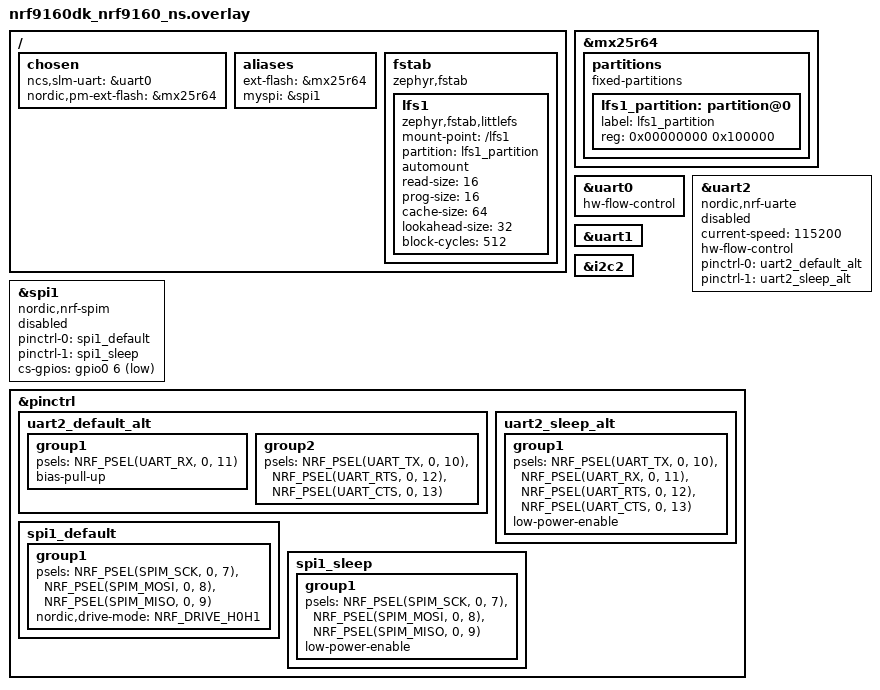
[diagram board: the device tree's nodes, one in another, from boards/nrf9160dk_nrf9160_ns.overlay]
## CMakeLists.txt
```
#
# Copyright (c) 2019 Nordic Semiconductor
#
# SPDX-License-Identifier: LicenseRef-Nordic-5-Clause
#

cmake_minimum_required(VERSION 3.20.0)

find_package(Zephyr REQUIRED HINTS $ENV{ZEPHYR_BASE})
project(serial_lte_modem)

# NORDIC SDK APP START
target_sources(app PRIVATE src/main.c)
target_sources(app PRIVATE src/slm_util.c)
target_sources(app PRIVATE src/slm_settings.c)
target_sources(app PRIVATE src/slm_at_host.c)
target_sources(app PRIVATE src/slm_at_commands.c)
# target_sources(app PRIVATE src/slm_at_socket.c)
# target_sources(app PRIVATE src/slm_at_tcp_proxy.c)
# target_sources(app PRIVATE src/slm_at_udp_proxy.c)
# target_sources(app PRIVATE src/slm_at_icmp.c)
target_sources(app PRIVATE src/slm_at_fota.c)
target_sources(app PRIVATE src/slm_uart_handler.c)
target_sources(app PRIVATE src/nvs_thread.c)
target_sources(app PRIVATE src/littlefs_thread.c)
# NORDIC SDK APP END
target_sources_ifdef(CONFIG_EXAMPLE_SPI app
                     PRIVATE src/spi_thread.c)					 
target_sources_ifdef(CONFIG_EXAMPLE_UART app
                     PRIVATE src/uart_thread.c)
target_sources_ifdef(CONFIG_SLM_SMS app PRIVATE src/slm_at_sms.c)
target_sources_ifdef(CONFIG_SLM_PPP app PRIVATE src/slm_ppp.c)
target_sources_ifdef(CONFIG_SLM_CMUX app PRIVATE src/slm_cmux.c)

add_subdirectory_ifdef(CONFIG_SLM_GNSS src/gnss)
add_subdirectory_ifdef(CONFIG_SLM_NRF_CLOUD src/nrfcloud)
add_subdirectory_ifdef(CONFIG_SLM_MQTTC src/mqtt_c)
add_subdirectory_ifdef(CONFIG_SLM_HTTPC src/http_c)
add_subdirectory_ifdef(CONFIG_SLM_TWI src/twi)
add_subdirectory_ifdef(CONFIG_SLM_GPIO src/gpio)
add_subdirectory_ifdef(CONFIG_SLM_CARRIER src/lwm2m_carrier)
add_subdirectory_ifdef(CONFIG_SLM_NATIVE_TLS src/nativetls)
if (CONFIG_SLM_FTPC OR CONFIG_SLM_TFTPC)
        add_subdirectory(src/ftp_c)
endif()

zephyr_include_directories(src)
```

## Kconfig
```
#
# Copyright (c) 2019 Nordic Semiconductor
#
# SPDX-License-Identifier: LicenseRef-Nordic-5-Clause
#

source "Kconfig.zephyr"

menu "Nordic Serial LTE Modem"

config EXAMPLE_SPI
	bool "load SPI master example or not"
	help
		if yes, load SPI master example

config EXAMPLE_UART
	bool "load high speed UART example or not"
	help
		if yes, load high speed UART example

config APP_WIPE_STORAGE
	bool "Option to clear the flash area before mounting"
	help
	  Use this to force an existing file system to be created.

choice
	prompt "Storage backend type used by the application"
	default APP_LITTLEFS_STORAGE_FLASH
	help
	  Specify the type of storage backend.

config APP_LITTLEFS_STORAGE_FLASH
	bool "Use flash memory backend"

config APP_LITTLEFS_STORAGE_BLK_SDMMC
	bool "Use block device (e.g. SD MMC) backend"
endchoice	

config SLM_CUSTOMER_VERSION
	string "Customer version string"
	help
	   This version is reported together with baseline versions by AT command "#XSLMVER".

config SLM_AT_MAX_PARAM
	int "Maximum number of parameters in AT command"
	default 42

#
# external XTAL for UART
#
config SLM_EXTERNAL_XTAL
	bool "Use external XTAL for UARTE"
	default y

#
# AT command terminator
#
choice
	prompt "Termination mode"
	default SLM_CR_LF_TERMINATION
	help
		Sets the command terminator used by the serial terminal.
		Available options are:
		-  CR termination
		-  LF termination
		-  CR+LF termination
	config SLM_CR_TERMINATION
		bool "CR termination"
	config SLM_LF_TERMINATION
		bool "LF termination"
	config SLM_CR_LF_TERMINATION
		bool "CR+LF termination"
endchoice

#
# UART buffers (when CMUX is not in use)
#
config SLM_UART_RX_BUF_COUNT
	int "Receive buffers for UART"
	range 2 4
	default 3
	help
	  Amount of buffers for receiving (RX) UART traffic. If the buffers are full, UART RX will be disabled until the buffers are processed.

config SLM_UART_RX_BUF_SIZE
	int "Receive buffer size for UART"
	range 128 4096
	default 256
	help
	  Amount of received (RX), unprocessed, UART traffic that can be held by single buffer.

config SLM_UART_TX_BUF_SIZE
	int "Send buffer size for UART"
	range 128 4096
	default 256
	help
	  Amount of UART traffic waiting to be sent (TX), that can be held. If the buffers are full, will send synchronously.

#
# GPIO functionality
#
config SLM_START_SLEEP
	bool "Enter sleep on startup"
	help
	  If enabled, the SiP is put into deep sleep when powered on.
	  It can then be started using SLM_POWER_PIN.

config SLM_POWER_PIN
	int "Power pin"
	default -1
	help
	  Interface GPIO pin used to put the SiP into deep sleep and wake up from it or exit idle.
	  The pin is configured with a pull up and must be pulled down shortly to perform one power off or wake up operation.

config SLM_INDICATE_PIN
	int "Indicate pin"
	default -1
	help
	  Interface GPIO pin used to indicate that data is available when SLM is idle (after #XSLEEP=2 AT command).

config SLM_INDICATE_TIME
	int "Indication period"
	default 100
	help
	  GPIO active indication time in milliseconds. This setting specify the period length for the pin to be active

#
# LTE network automatic attach
#
config SLM_AUTO_CONNECT
	bool "Automatically connect to the LTE network on start-up or after a reset"
	help
	  Enables automatic connection to the LTE network using the PDN configuration defined in 'slm_auto_connect.h'.

#
# TCP/TLS proxy
#
config SLM_TCP_POLL_TIME
	int "Poll time-out in seconds for TCP connection"
	default 10

config SLM_UDP_POLL_TIME
	int "Poll time-out in seconds for UDP connection"
	default 10

#
# Data mode
#
config SLM_DATAMODE_TERMINATOR
	string "Pattern string to terminate data mode"
	default "+++"
	help
	  Use a pattern to terminate data mode

config SLM_DATAMODE_URC
	bool "Send URC in data mode"
	help
	  Report result of data mode sending

config SLM_DATAMODE_BUF_SIZE
	int "Buffer size for data mode"
	range 1024 8192
	default 4096
	help
	  Size of the buffer for data received in data mode.

#
# Configurable services
#
config SLM_SMS
	bool "SMS support in SLM"
	default y
	select SMS
	help
	  Support SMS send/receive in plain text

config SLM_GNSS
	bool "GNSS support in SLM"
	default y

config SLM_NRF_CLOUD
	bool "nRF Cloud support in SLM"
	default y

config SLM_FULL_FOTA
	bool "Full modem FOTA support in SLM"
	default n
	depends on !BOARD_THINGY91_NRF9160_NS

config SLM_PPP
	bool "PPP support in SLM"
	help
	  When enabled, SLM automatically brings up/down the PPP link
	  when the LTE link (default PDN) is connected/disconnected,
	  regardless of what is done with AT#XPPP.

if SLM_PPP

config SLM_PPP_FALLBACK_MTU
	int "Fallback MTU to be used by PPP"
	default 1280
	help
	  PPP tries to retrieve the cellular link MTU from the modem (using `AT+CGCONTRDP=0`).
	  If no MTU is returned by the modem, this value will be used as a fallback.
	  The MTU will be used for sending and receiving of data on both the PPP and cellular links.

endif

config SLM_CMUX
	bool "CMUX support in SLM"

if SLM_CMUX && SLM_PPP

config SLM_CMUX_AUTOMATIC_FALLBACK_ON_PPP_STOPPAGE
	bool "AT channel automatic fallback to DLCI 1 when PPP stops."
	help
	  This is mainly intended for compatibility with Zephyr's cellular modem driver.
	  If enabled, when PPP stops (which happens automatically when the LTE link goes down)
	  CMUX will make the AT channel be on DLCI 1. This only has an effect if it had been
	  configured to be elsewhere, e.g. with AT#XCMUX=2.

endif

if SLM_CMUX || SLM_PPP

config SLM_MODEM_PIPE_TIMEOUT
	int "Timeout for the CMUX and PPP modem pipe operations in seconds"
	default 10

endif

module = SLM
module-str = serial modem
source "${ZEPHYR_BASE}/subsys/logging/Kconfig.template.log_config"

rsource "src/ftp_c/Kconfig"
rsource "src/mqtt_c/Kconfig"
rsource "src/http_c/Kconfig"
rsource "src/twi/Kconfig"
rsource "src/gpio/Kconfig"
rsource "src/lwm2m_carrier/Kconfig"
rsource "src/gnss/Kconfig"
rsource "src/nativetls/Kconfig"

endmenu
```

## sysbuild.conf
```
#
# Copyright (c) 2023 Nordic Semiconductor
#
# SPDX-License-Identifier: LicenseRef-Nordic-5-Clause
#

SB_CONFIG_BOOTLOADER_MCUBOOT=y
SB_CONFIG_PM_EXTERNAL_FLASH_MCUBOOT_SECONDARY=y
```

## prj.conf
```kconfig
#
# Copyright (c) 2020 Nordic Semiconductor ASA
#
# SPDX-License-Identifier: LicenseRef-Nordic-5-Clause
#
# General config
CONFIG_LOG=y
CONFIG_LOG_DEFAULT_LEVEL=3
CONFIG_STACK_SENTINEL=y
CONFIG_PICOLIBC_IO_FLOAT=y
CONFIG_RING_BUFFER=y
CONFIG_REBOOT=y
CONFIG_EVENTFD=y

# Segger RTT
CONFIG_USE_SEGGER_RTT=y
# Where console messages (printk) are output.
# By itself, SLM does not output any.
CONFIG_RTT_CONSOLE=y
CONFIG_UART_CONSOLE=y
# Where SLM logs are output.
CONFIG_LOG_BACKEND_RTT=y
CONFIG_LOG_BACKEND_UART=y

# Network
CONFIG_NETWORKING=y
CONFIG_NET_SOCKETS=y
CONFIG_NET_NATIVE=n
CONFIG_NET_IPV4=y
CONFIG_NET_IPV6=y

# Modem library
CONFIG_NRF_MODEM_LIB=y
CONFIG_AT_CMD_CUSTOM=y
# Align the max FD entry to NRF_MODEM_MAX_SOCKET_COUNT(8)
CONFIG_ZVFS_OPEN_MAX=8

# Handle modem fault
CONFIG_NRF_MODEM_LIB_ON_FAULT_APPLICATION_SPECIFIC=y

# Use GPIO
CONFIG_GPIO=y
CONFIG_GPIO_NRFX=y

# UART interface
CONFIG_SERIAL=y
CONFIG_UART_USE_RUNTIME_CONFIGURE=y
CONFIG_UART_ASYNC_API=y
CONFIG_NRFX_TIMER2=y

# Stacks and heaps
CONFIG_MAIN_STACK_SIZE=4096
CONFIG_HEAP_MEM_POOL_SIZE=16384
CONFIG_SYSTEM_WORKQUEUE_STACK_SIZE=4096
#CONFIG_AT_MONITOR_HEAP_SIZE=4096
CONFIG_AT_MONITOR_HEAP_SIZE=1024

# Device power management
CONFIG_PM_DEVICE=y

# FOTA
CONFIG_HTTP_PARSER_URL=y
CONFIG_FOTA_DOWNLOAD=y
CONFIG_FOTA_DOWNLOAD_PROGRESS_EVT=y
CONFIG_DFU_TARGET=y
CONFIG_DOWNLOAD_CLIENT=y
CONFIG_DOWNLOAD_CLIENT_STACK_SIZE=4096
CONFIG_DOWNLOAD_CLIENT_MAX_FILENAME_SIZE=2048
CONFIG_BOOTLOADER_MCUBOOT=y
CONFIG_IMG_MANAGER=y

# FLASH
CONFIG_FLASH=y
CONFIG_FLASH_PAGE_LAYOUT=y
CONFIG_FLASH_MAP=y
CONFIG_STREAM_FLASH=y
CONFIG_MPU_ALLOW_FLASH_WRITE=y
CONFIG_IMG_ERASE_PROGRESSIVELY=y

# Settings
CONFIG_SETTINGS=y
CONFIG_SETTINGS_NVS=y
CONFIG_NVS=y

# nRF Cloud
CONFIG_NRF_CLOUD_MQTT=n
CONFIG_NRF_CLOUD_FOTA=n
CONFIG_NRF_CLOUD_AGNSS=n
CONFIG_NRF_CLOUD_AGNSS_FILTERED=n
CONFIG_NRF_CLOUD_PGPS=n
CONFIG_NRF_CLOUD_LOCATION=n
CONFIG_NRF_CLOUD_LOG_LEVEL_INF=y
CONFIG_NRF_CLOUD_GPS_LOG_LEVEL_INF=y
CONFIG_NRF_CLOUD_CLIENT_ID_SRC_INTERNAL_UUID=y
CONFIG_NRF_CLOUD_WIFI_LOCATION_ENCODE_OPT_MAC_RSSI=y
CONFIG_DATE_TIME=n
CONFIG_MODEM_INFO=n
CONFIG_MODEM_INFO_ADD_DATE_TIME=n

# UUID and JWT
CONFIG_MODEM_JWT=y

# MQTT client
#CONFIG_MQTT_KEEPALIVE=60
CONFIG_MQTT_CLEAN_SESSION=y

# AT command helper libraries
CONFIG_AT_PARSER=y
CONFIG_AT_MONITOR=y

# Disable TF-M logging.
# TF-M log sending will block until remote end is ready, when HWFC is used on UART1.
CONFIG_TFM_LOG_LEVEL_SILENCE=y

#
# SLM-specific configurations
#
CONFIG_SLM_CUSTOMER_VERSION=""
CONFIG_SLM_EXTERNAL_XTAL=n

# debug options
#CONFIG_ASSERT=y
#CONFIG_LOG_BUFFER_SIZE=16384
#CONFIG_SLM_LOG_LEVEL_DBG=y
#CONFIG_LOG_PRINTK=n
#CONFIG_LOG_MODE_IMMEDIATE=y

# For using external GNSS antenna
#CONFIG_MODEM_ANTENNA=y
#CONFIG_MODEM_ANTENNA_GNSS_EXTERNAL=y

CONFIG_SLM_FTPC=n
CONFIG_SLM_TFTPC=n
CONFIG_SLM_NRF_CLOUD=n

CONFIG_NRF_MODEM_LIB_SHMEM_TX_SIZE=6272
CONFIG_NRF_MODEM_LIB_SHMEM_RX_SIZE=4096

# Enable external flash
CONFIG_SPI=y
CONFIG_SPI_NOR=y
CONFIG_SPI_NOR_SFDP_DEVICETREE=y
CONFIG_PM_OVERRIDE_EXTERNAL_DRIVER_CHECK=y

# use NVS instead since settings is used by the SLM as well
# CONFIG_PM_PARTITION_REGION_SETTINGS_STORAGE_EXTERNAL=y
# CONFIG_PM_PARTITION_SIZE_SETTINGS_STORAGE=0x200000

# select a proper value to fit your needs
CONFIG_SPI_NOR_FLASH_LAYOUT_PAGE_SIZE=4096
# CONFIG_SPI_NOR_SFDP_RUNTIME=y

# Optionally force the file system to be recreated
#CONFIG_APP_WIPE_STORAGE=y
CONFIG_FILE_SYSTEM=y
CONFIG_FILE_SYSTEM_LITTLEFS=y
CONFIG_APP_LITTLEFS_STORAGE_FLASH=y

CONFIG_SLM_TWI=y

CONFIG_EXAMPLE_UART=y
CONFIG_UART_1_ASYNC=y
CONFIG_NRFX_UARTE1=y
CONFIG_UART_1_NRF_HW_ASYNC=y
CONFIG_UART_1_NRF_HW_ASYNC_TIMER=1

CONFIG_EXAMPLE_SPI=n
# CONFIG_SPI=y
# CONFIG_NRFX_SPIM1=y
```

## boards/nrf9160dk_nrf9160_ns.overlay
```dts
/*
 * Copyright (c) 2021 Nordic Semiconductor ASA
 *
 * SPDX-License-Identifier: LicenseRef-Nordic-5-Clause
 */

/ {
	chosen {
		ncs,slm-uart = &uart0;
		nordic,pm-ext-flash = &mx25r64;
	};

	aliases {
		ext-flash = &mx25r64;
		myspi = &spi1;
	};
};

/ {
	fstab {
		compatible = "zephyr,fstab";
		lfs1: lfs1 {
			compatible = "zephyr,fstab,littlefs";
			mount-point = "/lfs1";
			partition = <&lfs1_partition>;
			automount;
			read-size = <16>;
			prog-size = <16>;
			cache-size = <64>;
			lookahead-size = <32>;
			block-cycles = <512>;
		};
	};
};

&mx25r64 {
	status = "okay";
	partitions {
		compatible = "fixed-partitions";
		#address-cells = <1>;
		#size-cells = <1>;

		lfs1_partition: partition@0 {
			label = "lfs1_partition";
			reg = <0x00000000 0x100000>;
		};
	};
};

&uart0 {
	status = "okay";
	hw-flow-control;
};

&uart2 {
	compatible = "nordic,nrf-uarte";
	current-speed = <115200>;
	status = "disabled";
	hw-flow-control;

	pinctrl-0 = <&uart2_default_alt>;
	pinctrl-1 = <&uart2_sleep_alt>;
	pinctrl-names = "default", "sleep";
};

my_uart: &uart1 {
	status = "okay";
	// current-speed = < 1000000 >;
	/delete-property/ hw-flow-control;
	/delete-property/ rts-pin;
	/delete-property/ cts-pin;
};

my_spi: &spi1 {
	status = "disabled"; 
	compatible = "nordic,nrf-spim";
	pinctrl-0 = <&spi1_default>;
	pinctrl-1 = <&spi1_sleep>;
	pinctrl-names = "default", "sleep";	
	cs-gpios = <&gpio0 6 GPIO_ACTIVE_LOW>;	
};

&i2c2 {
	status = "okay";
};

&pinctrl {
	uart2_default_alt: uart2_default_alt {
		group1 {
			psels = <NRF_PSEL(UART_RX, 0, 11)>;
			bias-pull-up;
		};
		group2 {
			psels = <NRF_PSEL(UART_TX, 0, 10)>,
				<NRF_PSEL(UART_RTS, 0, 12)>,
				<NRF_PSEL(UART_CTS, 0, 13)>;
		};
	};

	uart2_sleep_alt: uart2_sleep_alt {
		group1 {
			psels = <NRF_PSEL(UART_TX, 0, 10)>,
				<NRF_PSEL(UART_RX, 0, 11)>,
				<NRF_PSEL(UART_RTS, 0, 12)>,
				<NRF_PSEL(UART_CTS, 0, 13)>;
			low-power-enable;
		};
	};

	spi1_default: spi1_default {
		group1 {
			psels = <NRF_PSEL(SPIM_SCK, 0, 7)>,
				<NRF_PSEL(SPIM_MOSI, 0, 8)>,
				<NRF_PSEL(SPIM_MISO, 0, 9)>;
			nordic,drive-mode = <NRF_DRIVE_H0H1>;		
		};
	};

	spi1_sleep: spi1_sleep {
		group1 {
			psels = <NRF_PSEL(SPIM_SCK, 0, 7)>,
				<NRF_PSEL(SPIM_MOSI, 0, 8)>,
				<NRF_PSEL(SPIM_MISO, 0, 9)>;
			low-power-enable;
		};
	};

};
```

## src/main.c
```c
/*
 * Copyright (c) 2019 Nordic Semiconductor ASA
 *
 * SPDX-License-Identifier: LicenseRef-Nordic-5-Clause
 */
#include <zephyr/logging/log.h>
#include <zephyr/logging/log_ctrl.h>
#include <zephyr/kernel.h>
#include <assert.h>
#include <stdio.h>
#include <zephyr/drivers/uart.h>
#include <zephyr/drivers/gpio.h>
#include <string.h>
#include <nrf_modem.h>
#include <hal/nrf_gpio.h>
#include <hal/nrf_power.h>
#include <hal/nrf_regulators.h>
#include <modem/nrf_modem_lib.h>
#include <zephyr/dfu/mcuboot.h>
#include <dfu/dfu_target.h>
#include <zephyr/sys/reboot.h>
#include <zephyr/drivers/clock_control.h>
#include <zephyr/drivers/clock_control/nrf_clock_control.h>
#include <net/fota_download.h>
#include "slm_at_host.h"
#include "slm_at_fota.h"
#include "slm_settings.h"
#include "slm_util.h"

LOG_MODULE_REGISTER(slm, CONFIG_SLM_LOG_LEVEL);

#define SLM_WQ_STACK_SIZE	KB(4)
#define SLM_WQ_PRIORITY		K_LOWEST_APPLICATION_THREAD_PRIO
static K_THREAD_STACK_DEFINE(slm_wq_stack_area, SLM_WQ_STACK_SIZE);

static const struct device *gpio_dev = DEVICE_DT_GET(DT_NODELABEL(gpio0));
#if POWER_PIN_IS_ENABLED
static struct gpio_callback gpio_cb;
#else
BUILD_ASSERT(!IS_ENABLED(CONFIG_SLM_START_SLEEP),
	"CONFIG_SLM_START_SLEEP requires CONFIG_SLM_POWER_PIN to be defined.");
#endif
static struct k_work_delayable indicate_work;

struct k_work_q slm_work_q;

/* Forward declarations */
static void indicate_wk(struct k_work *work);

NRF_MODEM_LIB_ON_INIT(lwm2m_init_hook, on_modem_lib_init, NULL);
NRF_MODEM_LIB_ON_DFU_RES(main_dfu_hook, on_modem_dfu_res, NULL);

static void on_modem_lib_init(int ret, void *ctx)
{
	ARG_UNUSED(ctx);

	/** ret: Zero on success, a positive value @em nrf_modem_dfu when executing
	 *  Modem firmware updates, and negative errno on other failures.
	 */
	LOG_INF("lib_modem init: %d", ret);
}

#if defined(CONFIG_NRF_MODEM_LIB_ON_FAULT_APPLICATION_SPECIFIC)
static void on_modem_failure_shutdown(struct k_work *item);
static void on_modem_failure_reinit(struct k_work *item);

K_WORK_DELAYABLE_DEFINE(modem_failure_shutdown_work, on_modem_failure_shutdown);
K_WORK_DELAYABLE_DEFINE(modem_failure_reinit_work, on_modem_failure_reinit);

void nrf_modem_fault_handler(struct nrf_modem_fault_info *fault_info)
{
	rsp_send("\r\n#XMODEM: FAULT,0x%x,0x%x\r\n", fault_info->reason,
		fault_info->program_counter);
	/* For now we wait 10 ms to give the trace handler time to process trace data. */
	k_work_reschedule(&modem_failure_shutdown_work, K_MSEC(10));
}

static void on_modem_failure_shutdown(struct k_work *work)
{
	int ret = nrf_modem_lib_shutdown();

	ARG_UNUSED(work);
	rsp_send("\r\n#XMODEM: SHUTDOWN,%d\r\n", ret);
	k_work_reschedule(&modem_failure_reinit_work, K_MSEC(10));
}

static void on_modem_failure_reinit(struct k_work *work)
{
	int ret = nrf_modem_lib_init();

	ARG_UNUSED(work);
	rsp_send("\r\n#XMODEM: INIT,%d\r\n", ret);
}
#endif /* CONFIG_NRF_MODEM_LIB_ON_FAULT_APPLICATION_SPECIFIC */

static int ext_xtal_control(bool xtal_on)
{
	int err = 0;
#if defined(CONFIG_SLM_EXTERNAL_XTAL)
	static struct onoff_manager *clk_mgr;

	if (xtal_on) {
		struct onoff_client cli = {};

		/* request external XTAL for UART */
		clk_mgr = z_nrf_clock_control_get_onoff(CLOCK_CONTROL_NRF_SUBSYS_HF);
		sys_notify_init_spinwait(&cli.notify);
		err = onoff_request(clk_mgr, &cli);
		if (err < 0) {
			LOG_ERR("Clock request failed: %d", err);
			return err;
		}
		while (sys_notify_fetch_result(&cli.notify, &err) < 0) {
			/*empty*/
		}
	} else {
		/* release external XTAL for UART */
		err = onoff_release(clk_mgr);
		if (err < 0) {
			LOG_ERR("Clock release failed: %d", err);
			return err;
		}
	}
#endif

	return err;
}

#if POWER_PIN_IS_ENABLED

static int configure_power_pin_interrupt(gpio_callback_handler_t handler, gpio_flags_t flags)
{
	int err;
	const gpio_pin_t pin = CONFIG_SLM_POWER_PIN;

	/* First disable the previously configured interrupt. Somehow when in idle mode if
	 * the wake-up interrupt is configured to be on an edge the power consumption
	 * drastically increases (3x), which is is why it is configured to be level-triggered.
	 * When entering idle for some reason first disabling the previously edge-level
	 * configured interrupt is also needed to keep the power consumption down.
	 */
	gpio_pin_interrupt_configure(gpio_dev, pin, GPIO_INT_DISABLE);

	err = gpio_pin_interrupt_configure(gpio_dev, pin, flags);
	if (err) {
		LOG_ERR("Failed to configure %s (0x%x) on power pin. (%d)",
			"interrupt", flags, err);
		return err;
	}

	gpio_init_callback(&gpio_cb, handler, BIT(pin));

	err = gpio_add_callback(gpio_dev, &gpio_cb);
	if (err) {
		LOG_ERR("Failed to configure %s (0x%x) on power pin. (%d)", "callback", flags, err);
		return err;
	}

	LOG_DBG("Configured interrupt (0x%x) on power pin (%u).", flags, pin);
	return 0;
}

static void power_pin_callback_poweroff(const struct device *, struct gpio_callback *, uint32_t)
{
	LOG_INF("Power off triggered.");
	slm_enter_sleep();
}

static void poweroff_interrupt_enabler(struct k_work *)
{
	configure_power_pin_interrupt(power_pin_callback_poweroff, GPIO_INT_EDGE_RISING);
}

#endif /* POWER_PIN_IS_ENABLED */

#if POWER_PIN_IS_ENABLED || INDICATE_PIN_IS_ENABLED

static int configure_gpio(gpio_pin_t pin, gpio_flags_t flags)
{
	const int err = gpio_pin_configure(gpio_dev, pin, flags);

	if (err) {
		LOG_ERR("Failed to configure GPIO pin P0.%d. (%d)", pin, err);
		return err;
	}

	return 0;
}
#endif

static int init_gpios(void)
{
	if (!device_is_ready(gpio_dev)) {
		LOG_ERR("GPIO controller not ready");
		return -ENODEV;
	}

#if POWER_PIN_IS_ENABLED
	if (configure_gpio(CONFIG_SLM_POWER_PIN, GPIO_INPUT | GPIO_PULL_UP | GPIO_ACTIVE_LOW)) {
		return -1;
	}
#endif

#if INDICATE_PIN_IS_ENABLED
	if (configure_gpio(CONFIG_SLM_INDICATE_PIN, GPIO_OUTPUT_INACTIVE | GPIO_ACTIVE_LOW)) {
		return -1;
	}
#endif

	return 0;
}

int slm_indicate(void)
{
	int err = 0;

#if (INDICATE_PIN_IS_ENABLED)
	if (k_work_delayable_is_pending(&indicate_work)) {
		return 0;
	}
	LOG_DBG("Start indicating");
	err = gpio_pin_set(gpio_dev, CONFIG_SLM_INDICATE_PIN, 1);
	if (err) {
		LOG_ERR("GPIO_0 set error: %d", err);
	} else {
		k_work_reschedule(&indicate_work, K_MSEC(CONFIG_SLM_INDICATE_TIME));
	}
#endif
	return err;
}

static void indicate_stop(void)
{
#if (INDICATE_PIN_IS_ENABLED)
	if (gpio_pin_set(gpio_dev, CONFIG_SLM_INDICATE_PIN, 0) != 0) {
		LOG_WRN("GPIO_0 set error");
	}
	LOG_DBG("Stop indicating");
#endif
}

#if POWER_PIN_IS_ENABLED

static void power_pin_callback_enable_poweroff(const struct device *dev,
					       struct gpio_callback *gpio_callback, uint32_t)
{
	static K_WORK_DELAYABLE_DEFINE(work, poweroff_interrupt_enabler);

	LOG_DBG("Enabling the poweroff interrupt shortly...");
	gpio_remove_callback(dev, gpio_callback);

	/* Enable the poweroff interrupt after a small delay
	 * so that it doesn't fire right away (which it does if enabled here).
	 */
	k_work_schedule(&work, K_MSEC(1));
}

static void power_pin_callback_wakeup(const struct device *dev,
				      struct gpio_callback *gpio_callback, uint32_t)
{
	static atomic_t callback_running;
	int err;

	/* Prevent level triggered interrupt running this multiple times. */
	if (!atomic_cas(&callback_running, false, true)) {
		return;
	}

	LOG_INF("Resuming from idle.");
	if (k_work_delayable_is_pending(&indicate_work)) {
		k_work_cancel_delayable(&indicate_work);
		indicate_stop();
	}

	err = ext_xtal_control(true);
	if (err < 0) {
		LOG_WRN("Failed to enable ext XTAL: %d", err);
	}
	err = slm_at_host_power_on();
	if (err) {
		atomic_set(&callback_running, false);
		LOG_ERR("Failed to power on uart: %d", err);
		return;
	}

	gpio_remove_callback(dev, gpio_callback);

	/* Enable the poweroff interrupt only when the pin will be back to a nonactive state. */
	configure_power_pin_interrupt(power_pin_callback_enable_poweroff, GPIO_INT_EDGE_RISING);

	atomic_set(&callback_running, false);
}

void slm_enter_idle(void)
{
	LOG_INF("Entering idle.");
	int err;

	gpio_remove_callback(gpio_dev, &gpio_cb);

	err = configure_power_pin_interrupt(power_pin_callback_wakeup, GPIO_INT_LEVEL_LOW);
	if (err) {
		return;
	}

	err = ext_xtal_control(false);
	if (err < 0) {
		LOG_WRN("Failed to disable ext XTAL: %d", err);
	}
}

static void enter_sleep_no_uninit(void)
{
	LOG_INF("Entering sleep.");
	LOG_PANIC();
	nrf_gpio_cfg_sense_set(CONFIG_SLM_POWER_PIN, NRF_GPIO_PIN_SENSE_LOW);

	k_sleep(K_MSEC(100));

	nrf_regulators_system_off(NRF_REGULATORS_NS);
	assert(false);
}

void slm_enter_sleep(void)
{
	slm_at_host_uninit();

	/* Only power off the modem if it has not been put
	 * in flight mode to allow reducing NVM wear.
	 */
	if (!slm_is_modem_functional_mode(LTE_LC_FUNC_MODE_OFFLINE)) {
		slm_power_off_modem();
	}
	enter_sleep_no_uninit();
}

#endif /* POWER_PIN_IS_ENABLED */

void slm_enter_shutdown(void)
{
	LOG_INF("Entering shutdown.");

	/* De-configure GPIOs */
#if POWER_PIN_IS_ENABLED
	gpio_pin_interrupt_configure(gpio_dev, CONFIG_SLM_POWER_PIN, GPIO_INT_DISABLE);
	gpio_pin_configure(gpio_dev, CONFIG_SLM_POWER_PIN, GPIO_DISCONNECTED);
#endif
#if INDICATE_PIN_IS_ENABLED
	gpio_pin_configure(gpio_dev, CONFIG_SLM_INDICATE_PIN, GPIO_DISCONNECTED);
#endif

	k_sleep(K_MSEC(100));

	nrf_regulators_system_off(NRF_REGULATORS_NS);
	assert(false);
}

static void on_modem_dfu_res(int dfu_res, void *ctx)
{
	slm_fota_type = DFU_TARGET_IMAGE_TYPE_MODEM_DELTA;
	slm_fota_stage = FOTA_STAGE_COMPLETE;
	slm_fota_status = FOTA_STATUS_ERROR;
	slm_fota_info = dfu_res;

	switch (dfu_res) {
	case NRF_MODEM_DFU_RESULT_OK:
		LOG_INF("Modem update OK. Running new firmware.");
		slm_fota_status = FOTA_STATUS_OK;
		slm_fota_info = 0;
		break;
	case NRF_MODEM_DFU_RESULT_UUID_ERROR:
	case NRF_MODEM_DFU_RESULT_AUTH_ERROR:
		LOG_ERR("Modem update failed (0x%x). Running old firmware.", dfu_res);
		break;
	case NRF_MODEM_DFU_RESULT_HARDWARE_ERROR:
	case NRF_MODEM_DFU_RESULT_INTERNAL_ERROR:
		LOG_ERR("Fatal error (0x%x) encountered during modem update.", dfu_res);
		break;
	case NRF_MODEM_DFU_RESULT_VOLTAGE_LOW:
		LOG_ERR("Modem update postponed due to low voltage. "
			"Reset the modem once you have sufficient power.");
		slm_fota_stage = FOTA_STAGE_ACTIVATE;
		break;
	default:
		LOG_ERR("Unhandled nrf_modem DFU result code 0x%x.", dfu_res);
		break;
	}
}

static void check_app_fota_status(void)
{
	/** When a TEST image is swapped to primary partition and booted by MCUBOOT,
	 * the API mcuboot_swap_type() will return BOOT_SWAP_TYPE_REVERT. By this type
	 * MCUBOOT means that the TEST image is booted OK and, if it's not confirmed
	 * next, it'll be swapped back to secondary partition and original application
	 * image will be restored to the primary partition (so-called Revert).
	 */
	const int type = mcuboot_swap_type();

	switch (type) {
	/** Attempt to boot the contents of slot 0. */
	case BOOT_SWAP_TYPE_NONE:
		/* Normal reset, nothing happened, do nothing. */
		return;
	/** Swap to slot 1. Absent a confirm command, revert back on next boot. */
	case BOOT_SWAP_TYPE_TEST:
	/** Swap to slot 1, and permanently switch to booting its contents. */
	case BOOT_SWAP_TYPE_PERM:
	/** Swap failed because image to be run is not valid. */
	case BOOT_SWAP_TYPE_FAIL:
		slm_fota_status = FOTA_STATUS_ERROR;
		slm_fota_info = type;
		break;
	/** Swap back to alternate slot. A confirm changes this state to NONE. */
	case BOOT_SWAP_TYPE_REVERT:
		/* Happens on a successful application FOTA. */
		const int ret = boot_write_img_confirmed();

		slm_fota_info = ret;
		slm_fota_status = ret ? FOTA_STATUS_ERROR : FOTA_STATUS_OK;
		break;
	}
	slm_fota_type = DFU_TARGET_IMAGE_TYPE_MCUBOOT;
	slm_fota_stage = FOTA_STAGE_COMPLETE;
}

int lte_auto_connect(void)
{
	int err = 0;
#if defined(CONFIG_SLM_AUTO_CONNECT)
	int ret;
	int n;
	int stat;
	struct network_config {
		/* Refer to AT command manual of %XSYSTEMMODE for system mode settings */
		int lte_m_support;     /* 0 ~ 1 */
		int nb_iot_support;    /* 0 ~ 1 */
		int gnss_support;      /* 0 ~ 1 */
		int lte_preference;    /* 0 ~ 4 */
		/* Refer to AT command manual of +CGDCONT and +CGAUTH for PDN configuration */
		bool pdp_config;       /* PDP context definition required or not */
		char *pdn_fam;         /* PDP type: "IP", "IPV6", "IPV4V6", "Non-IP" */
		char *pdn_apn;         /* Access point name */
		int pdn_auth;          /* PDN authentication protocol 0(None), 1(PAP), 2(CHAP) */
		char *pdn_username;    /* PDN connection authentication username */
		char *pdn_password;    /* PDN connection authentication password */
	};
	const struct network_config cfg = {
#include "slm_auto_connect.h"
	};

	ret = slm_util_at_scanf("AT+CEREG?", "+CEREG: %d,%d", &n, &stat);
	if (ret != 2 || (stat == 1 || stat == 5)) {
		return 0;
	}

	LOG_INF("lte auto connect");
	err = slm_util_at_printf("AT%%XSYSTEMMODE=%d,%d,%d,%d", cfg.lte_m_support,
				  cfg.nb_iot_support, cfg.gnss_support, cfg.lte_preference);
	if (err) {
		LOG_ERR("Failed to configure system mode: %d", err);
		return err;
	}
	if (cfg.pdp_config) {
		err = slm_util_at_printf("AT+CGDCONT=0,%s,%s", cfg.pdn_fam, cfg.pdn_apn);
		if (err) {
			LOG_ERR("Failed to configure PDN: %d", err);
			return err;
		}
	}
	if (cfg.pdp_config && cfg.pdn_auth != 0) {
		err = slm_util_at_printf("AT+CGAUTH=0,%d,%s,%s", cfg.pdn_auth,
					  cfg.pdn_username, cfg.pdn_password);
		if (err) {
			LOG_ERR("Failed to configure AUTH: %d", err);
			return err;
		}
	}
	err = slm_util_at_printf("AT+CFUN=1");
	if (err) {
		LOG_ERR("Failed to turn on radio: %d", err);
		return err;
	}
#endif /* CONFIG_SLM_AUTO_CONNECT */

	return err;
}

int start_execute(void)
{
	int err;

	LOG_INF("Serial LTE Modem");
	err = ext_xtal_control(true);
	if (err < 0) {
		LOG_ERR("Failed to enable ext XTAL: %d", err);
		return err;
	}
	err = slm_at_host_init();
	if (err) {
		LOG_ERR("Failed to init at_host: %d", err);
		return err;
	}
#if POWER_PIN_IS_ENABLED
	/* Do not directly enable the poweroff interrupt so that only a full toggle triggers
	 * power off. This is because power on is triggered on low level, so if the pin is held
	 * down until SLM is fully initialized releasing it would directly trigger the power off.
	 */
	err = configure_power_pin_interrupt(power_pin_callback_enable_poweroff,
					    GPIO_INT_EDGE_FALLING);
#endif
	if (err) {
		return err;
	}
	k_work_queue_start(&slm_work_q, slm_wq_stack_area,
			   K_THREAD_STACK_SIZEOF(slm_wq_stack_area),
			   SLM_WQ_PRIORITY, NULL);
	(void)lte_auto_connect();

	return 0;
}

static void indicate_wk(struct k_work *work)
{
	ARG_UNUSED(work);

	indicate_stop();
}

int main(void)
{
	const uint32_t rr = nrf_power_resetreas_get(NRF_POWER_NS);

	nrf_power_resetreas_clear(NRF_POWER_NS, 0x70017);
	LOG_INF("Reset Reason: 0x%08x", rr);
	k_work_init_delayable(&indicate_work, indicate_wk);

	if (init_gpios() != 0) {
		LOG_WRN("Failed to init GPIO pins.");
	}
	/* Init and load settings */
	if (slm_settings_init() != 0) {
		LOG_WRN("Failed to init slm settings");
	}

#if defined(CONFIG_SLM_FULL_FOTA)
	if (slm_modem_full_fota) {
		slm_finish_modem_full_fota();
		slm_fota_type = DFU_TARGET_IMAGE_TYPE_FULL_MODEM;
	}
#endif

	const int ret = nrf_modem_lib_init();

	if (ret) {
		LOG_ERR("Modem library init failed, err: %d", ret);
		if (ret != -EAGAIN && ret != -EIO) {
			return ret;
		} else if (ret == -EIO) {
			LOG_ERR("Please program full modem firmware with the bootloader or "
				"external tools");
		}
	}

	check_app_fota_status();

#if defined(CONFIG_SLM_START_SLEEP)

	if (!(rr & NRF_POWER_RESETREAS_OFF_MASK)) { /* DETECT signal from GPIO */

		enter_sleep_no_uninit();
	}
#endif /* CONFIG_SLM_START_SLEEP */

	return start_execute();
}
```

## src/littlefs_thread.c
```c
/*
 * Copyright (c) 2022 Lukasz Majewski, DENX Software Engineering GmbH
 * Copyright (c) 2019 Peter Bigot Consulting, LLC
 *
 * SPDX-License-Identifier: Apache-2.0
 */

/* Sample which uses the filesystem API with littlefs */

#include <stdio.h>

#include <zephyr/kernel.h>
#include <zephyr/device.h>
#include <zephyr/fs/fs.h>
#include <zephyr/fs/littlefs.h>
#include <zephyr/logging/log.h>
#include <zephyr/storage/flash_map.h>

LOG_MODULE_REGISTER(main);

/* Matches LFS_NAME_MAX */
#define MAX_PATH_LEN 255
#define TEST_FILE_SIZE 547

static uint8_t file_test_pattern[TEST_FILE_SIZE];
static int lsdir(const char *path)
{
	int res;
	struct fs_dir_t dirp;
	static struct fs_dirent entry;

	fs_dir_t_init(&dirp);

	/* Verify fs_opendir() */
	res = fs_opendir(&dirp, path);
	if (res) {
		LOG_ERR("Error opening dir %s [%d]\n", path, res);
		return res;
	}

	LOG_PRINTK("\nListing dir %s ...\n", path);
	for (;;) {
		/* Verify fs_readdir() */
		res = fs_readdir(&dirp, &entry);

		/* entry.name[0] == 0 means end-of-dir */
		if (res || entry.name[0] == 0) {
			if (res < 0) {
				LOG_ERR("Error reading dir [%d]\n", res);
			}
			break;
		}

		if (entry.type == FS_DIR_ENTRY_DIR) {
			LOG_PRINTK("[DIR ] %s\n", entry.name);
		} else {
			LOG_PRINTK("[FILE] %s (size = %zu)\n",
				   entry.name, entry.size);
		}
	}

	/* Verify fs_closedir() */
	fs_closedir(&dirp);

	return res;
}

static int littlefs_increase_infile_value(char *fname)
{
	uint8_t boot_count = 0;
	struct fs_file_t file;
	int rc, ret;

	fs_file_t_init(&file);
	rc = fs_open(&file, fname, FS_O_CREATE | FS_O_RDWR);
	if (rc < 0) {
		LOG_ERR("FAIL: open %s: %d", fname, rc);
		return rc;
	}

	rc = fs_read(&file, &boot_count, sizeof(boot_count));
	if (rc < 0) {
		LOG_ERR("FAIL: read %s: [rd:%d]", fname, rc);
		goto out;
	}
	LOG_PRINTK("%s read count:%u (bytes: %d)\n", fname, boot_count, rc);

	rc = fs_seek(&file, 0, FS_SEEK_SET);
	if (rc < 0) {
		LOG_ERR("FAIL: seek %s: %d", fname, rc);
		goto out;
	}

	boot_count += 1;
	rc = fs_write(&file, &boot_count, sizeof(boot_count));
	if (rc < 0) {
		LOG_ERR("FAIL: write %s: %d", fname, rc);
		goto out;
	}

	LOG_PRINTK("%s write new boot count %u: [wr:%d]\n", fname,
		   boot_count, rc);

 out:
	ret = fs_close(&file);
	if (ret < 0) {
		LOG_ERR("FAIL: close %s: %d", fname, ret);
		return ret;
	}

	return (rc < 0 ? rc : 0);
}

static void incr_pattern(uint8_t *p, uint16_t size, uint8_t inc)
{
	uint8_t fill = 0x55;

	if (p[0] % 2 == 0) {
		fill = 0xAA;
	}

	for (int i = 0; i < (size - 1); i++) {
		if (i % 8 == 0) {
			p[i] += inc;
		} else {
			p[i] = fill;
		}
	}

	p[size - 1] += inc;
}

static void init_pattern(uint8_t *p, uint16_t size)
{
	uint8_t v = 0x1;

	memset(p, 0x55, size);

	for (int i = 0; i < size; i += 8) {
		p[i] = v++;
	}

	p[size - 1] = 0xAA;
}

static void print_pattern(uint8_t *p, uint16_t size)
{
	int i, j = size / 16, k;

	for (k = 0, i = 0; k < j; i += 16, k++) {
		LOG_PRINTK("%02x %02x %02x %02x %02x %02x %02x %02x ",
			   p[i], p[i+1], p[i+2], p[i+3],
			   p[i+4], p[i+5], p[i+6], p[i+7]);
		LOG_PRINTK("%02x %02x %02x %02x %02x %02x %02x %02x\n",
			   p[i+8], p[i+9], p[i+10], p[i+11],
			   p[i+12], p[i+13], p[i+14], p[i+15]);

		/* Mark 512B (sector) chunks of the test file */
		if ((k + 1) % 32 == 0) {
			LOG_PRINTK("\n");
		}
	}

	for (; i < size; i++) {
		LOG_PRINTK("%02x ", p[i]);
	}

	LOG_PRINTK("\n");
}

static int littlefs_binary_file_adj(char *fname)
{
	struct fs_dirent dirent;
	struct fs_file_t file;
	int rc, ret;

	/*
	 * Uncomment below line to force re-creation of the test pattern
	 * file on the littlefs FS.
	 */
	/* fs_unlink(fname); */
	fs_file_t_init(&file);

	rc = fs_open(&file, fname, FS_O_CREATE | FS_O_RDWR);
	if (rc < 0) {
		LOG_ERR("FAIL: open %s: %d", fname, rc);
		return rc;
	}

	rc = fs_stat(fname, &dirent);
	if (rc < 0) {
		LOG_ERR("FAIL: stat %s: %d", fname, rc);
		goto out;
	}

	/* Check if the file exists - if not just write the pattern */
	if (rc == 0 && dirent.type == FS_DIR_ENTRY_FILE && dirent.size == 0) {
		LOG_INF("Test file: %s not found, create one!",
			fname);
		init_pattern(file_test_pattern, sizeof(file_test_pattern));
	} else {
		rc = fs_read(&file, file_test_pattern,
			     sizeof(file_test_pattern));
		if (rc < 0) {
			LOG_ERR("FAIL: read %s: [rd:%d]",
				fname, rc);
			goto out;
		}
		incr_pattern(file_test_pattern, sizeof(file_test_pattern), 0x1);
	}

	LOG_PRINTK("------ FILE: %s ------\n", fname);
	print_pattern(file_test_pattern, sizeof(file_test_pattern));

	rc = fs_seek(&file, 0, FS_SEEK_SET);
	if (rc < 0) {
		LOG_ERR("FAIL: seek %s: %d", fname, rc);
		goto out;
	}

	rc = fs_write(&file, file_test_pattern, sizeof(file_test_pattern));
	if (rc < 0) {
		LOG_ERR("FAIL: write %s: %d", fname, rc);
	}

 out:
	ret = fs_close(&file);
	if (ret < 0) {
		LOG_ERR("FAIL: close %s: %d", fname, ret);
		return ret;
	}

	return (rc < 0 ? rc : 0);
}

#ifdef CONFIG_APP_LITTLEFS_STORAGE_FLASH
static int littlefs_flash_erase(unsigned int id)
{
	const struct flash_area *pfa;
	int rc;

	rc = flash_area_open(id, &pfa);
	if (rc < 0) {
		LOG_ERR("FAIL: unable to find flash area %u: %d\n",
			id, rc);
		return rc;
	}

	LOG_PRINTK("Area %u at 0x%x on %s for %u bytes\n",
		   id, (unsigned int)pfa->fa_off, pfa->fa_dev->name,
		   (unsigned int)pfa->fa_size);

	/* Optional wipe flash contents */
	if (IS_ENABLED(CONFIG_APP_WIPE_STORAGE)) {
		rc = flash_area_flatten(pfa, 0, pfa->fa_size);
		LOG_ERR("Erasing flash area ... %d", rc);
	}

	flash_area_close(pfa);
	return rc;
}
#define PARTITION_NODE DT_NODELABEL(lfs1)

#if DT_NODE_EXISTS(PARTITION_NODE)
FS_FSTAB_DECLARE_ENTRY(PARTITION_NODE);
#else /* PARTITION_NODE */
FS_LITTLEFS_DECLARE_DEFAULT_CONFIG(storage);
static struct fs_mount_t lfs_storage_mnt = {
	.type = FS_LITTLEFS,
	.fs_data = &storage,
	.storage_dev = (void *)FIXED_PARTITION_ID(storage_partition),
	.mnt_point = "/lfs",
};
#endif /* PARTITION_NODE */

	struct fs_mount_t *mountpoint =
#if DT_NODE_EXISTS(PARTITION_NODE)
		&FS_FSTAB_ENTRY(PARTITION_NODE)
#else
		&lfs_storage_mnt
#endif
		;

static int littlefs_mount(struct fs_mount_t *mp)
{
	int rc;

	rc = littlefs_flash_erase((uintptr_t)mp->storage_dev);
	if (rc < 0) {
		return rc;
	}

	/* Do not mount if auto-mount has been enabled */
#if !DT_NODE_EXISTS(PARTITION_NODE) ||						\
	!(FSTAB_ENTRY_DT_MOUNT_FLAGS(PARTITION_NODE) & FS_MOUNT_FLAG_AUTOMOUNT)
	rc = fs_mount(mp);
	if (rc < 0) {
		LOG_PRINTK("FAIL: mount id %" PRIuPTR " at %s: %d\n",
		       (uintptr_t)mp->storage_dev, mp->mnt_point, rc);
		return rc;
	}
	LOG_PRINTK("%s mount: %d\n", mp->mnt_point, rc);
#else
	LOG_PRINTK("%s automounted\n", mp->mnt_point);
#endif

	return 0;
}
#endif /* CONFIG_APP_LITTLEFS_STORAGE_FLASH */

#ifdef CONFIG_APP_LITTLEFS_STORAGE_BLK_SDMMC

#if defined(CONFIG_DISK_DRIVER_SDMMC)
#define DISK_NAME CONFIG_SDMMC_VOLUME_NAME
#elif defined(CONFIG_DISK_DRIVER_MMC)
#define DISK_NAME CONFIG_MMC_VOLUME_NAME
#else
#error "No disk device defined, is your board supported?"
#endif

struct fs_littlefs lfsfs;
static struct fs_mount_t __mp = {
	.type = FS_LITTLEFS,
	.fs_data = &lfsfs,
	.flags = FS_MOUNT_FLAG_USE_DISK_ACCESS,
};
struct fs_mount_t *mountpoint = &__mp;

static int littlefs_mount(struct fs_mount_t *mp)
{
	static const char *disk_mount_pt = "/"DISK_NAME":";
	static const char *disk_pdrv = DISK_NAME;

	mp->storage_dev = (void *)disk_pdrv;
	mp->mnt_point = disk_mount_pt;

	return fs_mount(mp);
}
#endif /* CONFIG_APP_LITTLEFS_STORAGE_BLK_SDMMC */

void littlefs_thread(void)
{
	char fname1[MAX_PATH_LEN];
	char fname2[MAX_PATH_LEN];
	struct fs_statvfs sbuf;
	int rc;

	LOG_PRINTK("Sample program to r/w files on littlefs\n");

	rc = littlefs_mount(mountpoint);
	if (rc < 0) {
		goto out;
	}

	snprintf(fname1, sizeof(fname1), "%s/boot_count", mountpoint->mnt_point);
	snprintf(fname2, sizeof(fname2), "%s/pattern.bin", mountpoint->mnt_point);

	rc = fs_statvfs(mountpoint->mnt_point, &sbuf);
	if (rc < 0) {
		LOG_PRINTK("FAIL: statvfs: %d\n", rc);
		goto out;
	}

	LOG_PRINTK("%s: bsize = %lu ; frsize = %lu ;"
		   " blocks = %lu ; bfree = %lu\n",
		   mountpoint->mnt_point,
		   sbuf.f_bsize, sbuf.f_frsize,
		   sbuf.f_blocks, sbuf.f_bfree);

	rc = lsdir(mountpoint->mnt_point);
	if (rc < 0) {
		LOG_PRINTK("FAIL: lsdir %s: %d\n", mountpoint->mnt_point, rc);
		goto out;
	}

	rc = littlefs_increase_infile_value(fname1);
	if (rc) {
		goto out;
	}

	rc = littlefs_binary_file_adj(fname2);
	if (rc) {
		goto out;
	}

out:
	rc = fs_unmount(mountpoint);
	LOG_PRINTK("%s unmount: %d\n", mountpoint->mnt_point, rc);	
}

K_THREAD_DEFINE(littlefs_thread_id, 4096, littlefs_thread, NULL, NULL,
				NULL, 9, 0, 0);
```

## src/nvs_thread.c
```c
/*
 * Copyright (c) 2020 Nordic Semiconductor ASA
 *
 * SPDX-License-Identifier: LicenseRef-BSD-5-Clause-Nordic
 */

#include <zephyr/kernel.h>
#include <zephyr/device.h>
#include <string.h>
#include <zephyr/drivers/flash.h>
#include <zephyr/storage/flash_map.h>
#include <zephyr/fs/nvs.h>
#include <zephyr/settings/settings.h>
#include <zephyr/logging/log.h>

#define LOG_MODULE_NAME nvs_thread
LOG_MODULE_REGISTER(LOG_MODULE_NAME);

#define NVS_LABEL nvs_fs
static struct nvs_fs fs;

#define NVS_ID_TEST 3
#define NVS_ID_KEY 4
#define NVS_ID_CNT 5
static uint8_t key[8];
static uint32_t reboot_counter = 0U;
static uint8_t test_data[256];	

static int nvs_usage_init(void)
{
	int rc;
	struct flash_pages_info info;
	const struct flash_area *fa;

	//erase the whole area first
	rc = flash_area_open(PM_NVS_FS_ID, &fa);
	if (rc) {
		printk("flash_area_open err:%d\n", rc);
		return -EINVAL;
	}

	flash_area_read(fa, 0x1000, test_data, 256);
	// LOG_INF("external Flash read: 0x%x ~ 0x%x",
	// 			test_data[0], test_data[255]);

	// LOG_INF("erasing the whole external SIMULATION RAM Flash area");
	// LOG_INF("Please wait......");
	// rc = flash_area_erase(fa, 0, PM_RAM_SIM_SIZE);   //PM_RAM_SIM_SIZE
	// if (rc) {
	// 	printk("flash_area_erase err:%d\n", rc);
	// 	return -EINVAL;
	// }	

	fs.flash_device = FLASH_AREA_DEVICE(NVS_LABEL);
	if (!device_is_ready(fs.flash_device)) {
		printk("Flash device %s is not ready\n", fs.flash_device->name);
		return -EINVAL;
	}
	fs.offset = FLASH_AREA_OFFSET(NVS_LABEL);
	rc = flash_get_page_info_by_offs(fs.flash_device, fs.offset, &info);
	if (rc) {
		printk("Unable to get page info\n");
		return -EINVAL;
	}
	fs.sector_size = info.size;
	fs.sector_count = PM_NVS_FS_SIZE / info.size;

	LOG_INF("NVS sector_size=%d sector_count=%d\n", fs.sector_size, fs.sector_count);
	
	rc = nvs_mount(&fs);
	if (rc)
	{
		LOG_ERR("NVS Init failed %d", rc);
		return -EINVAL;
	}

	return 0;
}

static int flash_access(void)
{
	int rc;

	/* NVS_ID_KEY is used to store a key, lets see if we can read it from flash
	 */
	rc = nvs_read(&fs, NVS_ID_KEY, &key, sizeof(key));
	if (rc > 0)
	{ /* item was found, show it */
		LOG_HEXDUMP_INF(key, sizeof(key), "Key value in NVS:");
	}
	else
	{ /* item was not found, add it */
		LOG_INF("No key found, adding it at id %d by NVS API", NVS_ID_KEY);
		key[0] = 0xFF;
		key[1] = 0xFE;
		key[2] = 0xFD;
		key[3] = 0xFC;
		key[4] = 0xFB;
		key[5] = 0xFA;
		key[6] = 0xF9;
		key[7] = 0xF8;
		rc = nvs_write(&fs, NVS_ID_KEY, &key, sizeof(key));
		if (rc != sizeof(key))
		{
			LOG_ERR("nvs_write key err:%d", rc);
		}
	}
	/* NVS_ID_CNT is used to store the reboot counter, lets see
	 * if we can read it from flash
	 */	
	rc = nvs_read(&fs, NVS_ID_CNT, &reboot_counter, sizeof(reboot_counter));
	if (rc > 0)
	{ /* item was found, show it */
		LOG_INF("*** Reboot counter in NVS: %d ***",
				reboot_counter);
	}
	else
	{
		LOG_ERR("nvs_read reboot_counter err:%d", rc);
	}

	LOG_INF("save new reboot counter by NVS API");
	reboot_counter++;
	rc = nvs_write(&fs, NVS_ID_CNT, &reboot_counter,
					sizeof(reboot_counter));
	if (rc != sizeof(reboot_counter))
	{
		LOG_ERR("nvs_write reboot_counter err:%d", rc);
	}

	LOG_INF("save test_data by NVS API");	
	memset(test_data, reboot_counter, sizeof(test_data));
	rc = nvs_write(&fs, NVS_ID_TEST, &test_data,
					sizeof(test_data));
	if (rc != sizeof(test_data))
	{
		LOG_ERR("nvs_write test_data err:%d", rc);
	}	

	rc = nvs_read(&fs, NVS_ID_TEST, &test_data, sizeof(test_data));
	if (rc > 0)
	{ /* item was found, show it */
		LOG_INF("test_data: 0x%x ~ 0x%x in NVS",
				test_data[0], test_data[255]);
	}
	else
	{
		LOG_ERR("nvs_read test data err:%d", rc);
	}


	return 0;

}

void nvs_thread(void)
{
	int rc;

	LOG_INF("File system sample on external Flash");

	//let other works finish first
	k_sleep(K_SECONDS(1));

	rc = nvs_usage_init();
	if (rc)
	{
		LOG_ERR("nvs init failed %d", rc);
		return;
	}	

	while (1)   //exit
	{
		k_msleep(5000);
		flash_access();		
	}
}

K_THREAD_DEFINE(nvs_thread_id, 1024, nvs_thread, NULL, NULL,
				NULL, 9, 0, 0);
```

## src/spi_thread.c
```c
/*
 * Copyright (c) 2020 Nordic Semiconductor ASA
 *
 * SPDX-License-Identifier: LicenseRef-BSD-5-Clause-Nordic
 */

#include <zephyr/kernel.h>
#include <zephyr/device.h>
#include <zephyr/devicetree.h>
#include <zephyr/drivers/gpio.h>
#include <zephyr/logging/log.h>
#include <zephyr/drivers/spi.h>

#define LOG_MODULE_NAME spi_thread
LOG_MODULE_REGISTER(LOG_MODULE_NAME);

#define DELAY_SPI_CS_ACTIVE_US 2
#define TEST_STRING "Nordic"

const struct device *spi_dev;

static int spi_data_exchange(void)
{
    int err;
    struct spi_config spi_cfg = {0};

	spi_cfg.frequency = 8000000U;
	spi_cfg.operation = SPI_WORD_SET(8);

	spi_cfg.cs.gpio.port = DEVICE_DT_GET(DT_GPIO_CTLR(DT_ALIAS(myspi), cs_gpios));
	if (!spi_cfg.cs.gpio.port) {
        LOG_ERR("cannot find CS GPIO device");
		return -ENODEV;
	}

	spi_cfg.cs.gpio.pin = DT_GPIO_PIN(DT_ALIAS(myspi), cs_gpios);
	spi_cfg.cs.gpio.dt_flags = DT_GPIO_FLAGS(DT_ALIAS(myspi), cs_gpios);

	spi_cfg.cs.delay = DELAY_SPI_CS_ACTIVE_US;

	uint8_t buf[] = TEST_STRING;
    uint8_t data[] = TEST_STRING;

	struct spi_buf spi_buf[2] = {
		{
			.buf = buf,
			.len = sizeof(buf),
		},
		{
			.buf = data,
			.len = sizeof(data)
		}
	};
    
	const struct spi_buf_set tx_set = {
		.buffers = spi_buf,
		.count = 1
	};

	const struct spi_buf_set rx_set = {
		.buffers = spi_buf,
		.count = 1
	};

	// const struct spi_buf_set tx_set = {
	// 	.buffers = spi_buf,
	// 	.count = 2
	// };

	// const struct spi_buf_set rx_set = {
	// 	.buffers = spi_buf,
	// 	.count = 2
	// };    

	err = spi_transceive(spi_dev, &spi_cfg, &tx_set, &rx_set);
    
    if (err)
    {
        LOG_ERR("SPI transcation failed err %d", err);
    }
    else
    {
        LOG_HEXDUMP_INF(rx_set.buffers->buf, rx_set.buffers->len, "Received SPI data: ");
    }

    return err;

}

void spi_thread(void)
{	
	
	LOG_INF("** SPI master example **");
	LOG_INF("This example is ported from nRF5_SDK\\examples\\peripheral\\spi");
	LOG_INF("The related spis example is from nRF5_SDK\\examples\\peripheral\\spis");
	
	spi_dev = DEVICE_DT_GET(DT_ALIAS(myspi));
	if (!spi_dev) {
		LOG_ERR("SPIM driver not found.\n");
		return;
	}

	while (1) {                
        LOG_INF("spi master thread");
        spi_data_exchange();
        k_sleep(K_MSEC(2000)); 
	}
}

K_THREAD_DEFINE(spi_thread_id, 1024, spi_thread, NULL, NULL,
		NULL, 7, 0, 0);
```

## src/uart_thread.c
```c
/*
 * Copyright (c) 2020 Nordic Semiconductor ASA
 *
 * SPDX-License-Identifier: LicenseRef-BSD-5-Clause-Nordic
 */

#include <zephyr/kernel.h>
#include <zephyr/device.h>
#include <zephyr/devicetree.h>
#include <zephyr/drivers/gpio.h>
#include <stdio.h>
#include <zephyr/logging/log.h>
#include <zephyr/drivers/uart.h>
#include <zephyr/drivers/gpio.h>
#include <bluetooth/services/nus.h>

#define LOG_MODULE_NAME uart_thread
LOG_MODULE_REGISTER(LOG_MODULE_NAME);

#define UART_DEVICE_NAME         DT_NODELABEL(uart1)

#define UART_BUF_SIZE 255
#define UART_WAIT_FOR_BUF_DELAY K_MSEC(100)
#define UART_WAIT_FOR_RX 10000

static const struct device *uart;

struct uart_data_t {
	void *fifo_reserved;
	uint8_t data[UART_BUF_SIZE];
	uint16_t len;
};

static uint8_t uart_rx_buf[2][UART_BUF_SIZE];
static uint8_t *next_buf = uart_rx_buf[1];

static K_FIFO_DEFINE(fifo_uart_tx_data);
static K_FIFO_DEFINE(fifo_uart_rx_data);


static void uart_cb(const struct device *dev, struct uart_event *evt, void *user_data)
{
	ARG_UNUSED(dev);
	int err;

	switch (evt->type) {
	case UART_TX_DONE:
	{
		struct uart_data_t *buf;
		struct uart_data_t *buf2;
		
		buf = CONTAINER_OF(evt->data.tx.buf, struct uart_data_t,  data[0]);		
		LOG_INF("UART_TX_DONE %d", evt->data.tx.len);
		k_free(buf);

		buf2 = k_fifo_get(&fifo_uart_tx_data, K_NO_WAIT);
		if (!buf2) {
			return;
		}

		if (uart_tx(uart, buf2->data, buf2->len, SYS_FOREVER_MS)) {
			LOG_WRN("uart_tx fail @ cb");
		}
	}
		break;

	case UART_RX_RDY:
	{
		struct uart_data_t *buf = k_malloc(sizeof(struct uart_data_t));
		memcpy(buf->data, &evt->data.rx.buf[evt->data.rx.offset], evt->data.rx.len);	
		buf->len = evt->data.rx.len;		
		k_fifo_put(&fifo_uart_rx_data, buf);
		LOG_INF("UART_RX_RDY %d", buf->len);
	}
		break;

	case UART_RX_DISABLED:
		LOG_INF("UART_RX_DISABLED");
	#ifndef CONFIG_UART_ASYNC_API
		err = uart_rx_enable(uart, uart_rx_buf[0], sizeof(uart_rx_buf[0]), UART_WAIT_FOR_RX);
		if (err) {
			LOG_ERR("UART RX enable failed: %d", err);			
		}
	#endif
		break;

	case UART_RX_BUF_REQUEST:
		err = uart_rx_buf_rsp(uart, next_buf,
			sizeof(uart_rx_buf[0]));
		if (err) {
			LOG_WRN("UART RX buf rsp: %d", err);
		}		
		break;

	case UART_RX_BUF_RELEASED:
		LOG_INF("UART_RX_BUF_RELEASED");
		next_buf = evt->data.rx_buf.buf;
		break;

	case UART_TX_ABORTED:
		LOG_INF("UART_TX_ABORTED");
		break;

	default:
		break;
	}
}

static int uart_init(void)
{
	int err;
	
	uart = DEVICE_DT_GET(UART_DEVICE_NAME);
	if (!uart) {
		return -ENXIO;
	}

	err = uart_callback_set(uart, uart_cb, NULL);
	if (err) {
		return err;
	}

	return uart_rx_enable(uart, uart_rx_buf[0], sizeof(uart_rx_buf[0]), UART_WAIT_FOR_RX);

}

int my_uart_enable()
{
	next_buf = uart_rx_buf[1];
	return uart_rx_enable(uart, uart_rx_buf[0], sizeof(uart_rx_buf[0]), UART_WAIT_FOR_RX);
}

int my_uart_send(const uint8_t *buf, size_t len)
{
	int err;
	struct uart_data_t *tx = k_malloc(sizeof(*tx));

	if (!tx) {
		LOG_WRN("Not able to allocate UART send data buffer");
		return -ENOMEM; 
	}

	memcpy(tx->data, buf, len);	
	tx->len = len;
	err = uart_tx(uart, tx->data, tx->len, SYS_FOREVER_MS);
	if (err) {
		LOG_WRN("buffer uart tx data for later retry (err %d)", err);
		k_fifo_put(&fifo_uart_tx_data, tx);
	}
	return err;		
}

void uart_thread(void)
{
	LOG_INF("**high speed UART example");

	uart_init();

	while (1) {

		/* Send the UART data back to the peer. Wait indefinitely*/
		struct uart_data_t *buf = k_fifo_get(&fifo_uart_rx_data,
						     K_FOREVER);

		my_uart_send(buf->data,buf->len);
		
		// LOG_HEXDUMP_INF(buf->data, buf->len, "uart received:");
		k_free(buf);					
	}
}

K_THREAD_DEFINE(uart_thread_id, 1024, uart_thread, NULL, NULL,
		NULL, 5, 0, 0);
```
